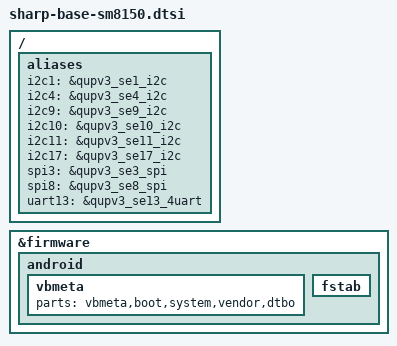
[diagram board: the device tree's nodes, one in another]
/* Copyright (c) 2017, The Linux Foundation. All rights reserved.
 *
 * This program is free software; you can redistribute it and/or modify
 * it under the terms of the GNU General Public License version 2 and
 * only version 2 as published by the Free Software Foundation.
 *
 * This program is distributed in the hope that it will be useful,
 * but WITHOUT ANY WARRANTY; without even the implied warranty of
 * MERCHANTABILITY or FITNESS FOR A PARTICULAR PURPOSE.  See the
 * GNU General Public License for more details.
 */

/*****************************************/
/* alieas                                */
/*****************************************/
/ {
    aliases {
        /delete-property/ hsuart0;
        /delete-property/ spi0;
        /delete-property/ i2c0;

        i2c1   = &qupv3_se1_i2c;
        i2c4   = &qupv3_se4_i2c;
        i2c9   = &qupv3_se9_i2c;
        i2c10  = &qupv3_se10_i2c;
        i2c11  = &qupv3_se11_i2c;
        i2c17  = &qupv3_se17_i2c;
        spi3   = &qupv3_se3_spi;
        spi8   = &qupv3_se8_spi;
        uart13 = &qupv3_se13_4uart;
    };
};


/*****************************************/
/* Delete Qualcomm node/property         */
/*****************************************/

/*****************************************/
/*  Add SHARP include                    */
/*****************************************/
#include "storage/sharp-base-sm8150-sdcc.dtsi"
/* SH_AUDIO_DRIVER -> */ /*A-001*/
#include "shaudio/sharp-base-sdm845-shaudio.dtsi"
/* SH_AUDIO_DRIVER <- */ /*A-001*/
/* SH_DISPLAY_DRIVER -> */ /* CUST_ID_00011 */
#include "shdisp/sharp-base-sm8150-shdisp.dtsi"
/* SH_DISPLAY_DRIVER <- */ /* CUST_ID_00011 */


/*******************************************/
/* Modify Qualcomm node/property           */
/*******************************************/
&firmware {
	android {
		vbmeta {
			parts = "vbmeta,boot,system,vendor,dtbo";
		};
		fstab {
			/delete-node/ vm-linux;
		};
	};
};

